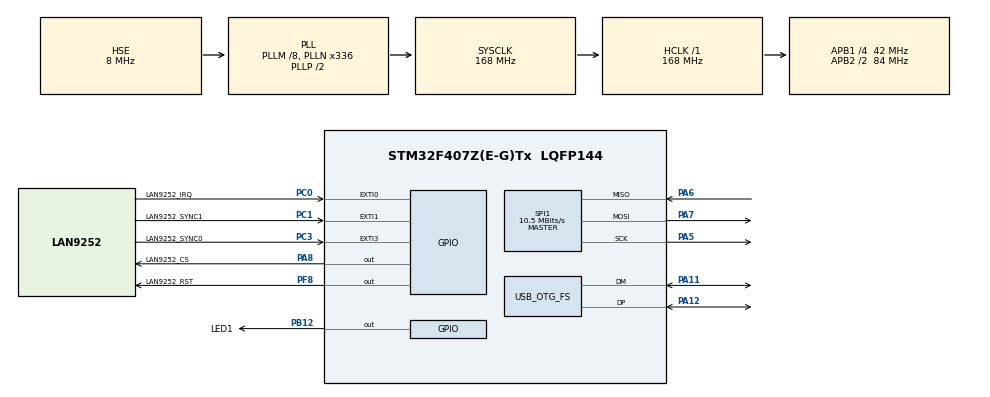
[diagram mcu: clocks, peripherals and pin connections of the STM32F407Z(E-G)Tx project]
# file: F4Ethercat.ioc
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FREERTOS.Tasks01=defaultTask,24,128,StartDefaultTask,Default,NULL,Dynamic,NULL,NULL
Mcu.Family=STM32F4
Mcu.Name=STM32F407Z(E-G)Tx
Mcu.Package=LQFP144
NVIC.EXTI0_IRQn=true\:5\:0\:false\:false\:true\:true\:true\:true\:true
NVIC.EXTI1_IRQn=true\:5\:0\:false\:false\:true\:true\:true\:true\:true
NVIC.EXTI3_IRQn=true\:5\:0\:false\:false\:true\:true\:true\:true\:true
NVIC.OTG_FS_IRQn=true\:5\:0\:false\:false\:true\:true\:false\:true\:true
NVIC.PriorityGroup=NVIC_PRIORITYGROUP_4
PA11.Mode=Device_Only
PA11.Signal=USB_OTG_FS_DM
PA12.Mode=Device_Only
PA12.Signal=USB_OTG_FS_DP
PA13.Mode=Serial_Wire
PA13.Signal=SYS_JTMS-SWDIO
PA14.Mode=Serial_Wire
PA14.Signal=SYS_JTCK-SWCLK
PA5.Mode=Full_Duplex_Master
PA5.Signal=SPI1_SCK
PA6.Mode=Full_Duplex_Master
PA6.Signal=SPI1_MISO
PA7.Mode=Full_Duplex_Master
PA7.Signal=SPI1_MOSI
PA8.GPIO_Label=LAN9252_CS
PA8.GPIO_Speed=GPIO_SPEED_FREQ_VERY_HIGH
PA8.PinState=GPIO_PIN_SET
PA8.Signal=GPIO_Output
PB12.GPIO_Label=LED1
PB12.PinState=GPIO_PIN_SET
PB12.Signal=GPIO_Output
PC0.GPIO_Label=LAN9252_IRQ
PC0.GPIO_ModeDefaultEXTI=GPIO_MODE_IT_FALLING
PC0.GPIO_PuPd=GPIO_PULLUP
PC0.Signal=GPXTI0
PC1.GPIO_Label=LAN9252_SYNC1
PC1.GPIO_ModeDefaultEXTI=GPIO_MODE_IT_FALLING
PC1.GPIO_PuPd=GPIO_PULLUP
PC1.Signal=GPXTI1
PC3.GPIO_Label=LAN9252_SYNC0
PC3.GPIO_ModeDefaultEXTI=GPIO_MODE_IT_FALLING
PC3.GPIO_PuPd=GPIO_PULLUP
PC3.Signal=GPXTI3
PF8.GPIO_Label=LAN9252_RST
PF8.GPIO_ModeDefaultOutputPP=GPIO_MODE_OUTPUT_OD
PF8.PinState=GPIO_PIN_SET
PF8.Signal=GPIO_Output
PH0-OSC_IN.Mode=HSE-External-Oscillator
PH0-OSC_IN.Signal=RCC_OSC_IN
PH1-OSC_OUT.Mode=HSE-External-Oscillator
PH1-OSC_OUT.Signal=RCC_OSC_OUT
ProjectManager.HeapSize=0x400
ProjectManager.StackSize=0x600
ProjectManager.TargetToolchain=CMake
RCC.48MHZClocksFreq_Value=48000000
RCC.AHBFreq_Value=168000000
RCC.APB1CLKDivider=RCC_HCLK_DIV4
RCC.APB1Freq_Value=42000000
RCC.APB1TimFreq_Value=84000000
RCC.APB2CLKDivider=RCC_HCLK_DIV2
RCC.APB2Freq_Value=84000000
RCC.APB2TimFreq_Value=168000000
RCC.CortexFreq_Value=168000000
RCC.HCLKFreq_Value=168000000
RCC.HSE_VALUE=8000000
RCC.HSI_VALUE=16000000
RCC.LSE_VALUE=32768
RCC.PLLM=8
RCC.PLLN=336
RCC.PLLQ=7
RCC.SYSCLKFreq_VALUE=168000000
RCC.SYSCLKSource=RCC_SYSCLKSOURCE_PLLCLK
RCC.VCOOutputFreq_Value=336000000
SPI1.BaudRatePrescaler=SPI_BAUDRATEPRESCALER_8
SPI1.CalculateBaudRate=10.5 MBits/s
SPI1.Direction=SPI_DIRECTION_2LINES
SPI1.Mode=SPI_MODE_MASTER
SPI1.VirtualType=VM_MASTER
USB_DEVICE.CLASS_NAME_FS=CDC
USB_DEVICE.VirtualMode-CDC_FS=Cdc
USB_DEVICE.VirtualModeFS=Cdc_FS
USB_OTG_FS.VirtualMode=Device_Only
VP_FREERTOS_VS_CMSIS_V2.Mode=CMSIS_V2
VP_USB_DEVICE_VS_USB_DEVICE_CDC_FS.Mode=CDC_FS
board=custom

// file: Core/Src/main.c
/* USER CODE BEGIN Header */
/**
  ******************************************************************************
  * @file           : main.c
  * @brief          : Main program body
  ******************************************************************************
  * @attention
  *
  * Copyright (c) 2026 STMicroelectronics.
  * All rights reserved.
  *
  * This software is licensed under terms that can be found in the LICENSE file
  * in the root directory of this software component.
  * If no LICENSE file comes with this software, it is provided AS-IS.
  *
  ******************************************************************************
  */
/* USER CODE END Header */
#include "main.h"
#include "cmsis_os.h"
#include "usb_device.h"

/* USER CODE BEGIN Includes */
#include "ecat_app.h"
/* USER CODE END Includes */

SPI_HandleTypeDef hspi1;

/* Definitions for defaultTask */
osThreadId_t defaultTaskHandle;
const osThreadAttr_t defaultTask_attributes = {
  .name = "defaultTask",
  .stack_size = 128 * 4,
  .priority = (osPriority_t) osPriorityNormal,
};
/* USER CODE BEGIN PV */
osThreadId_t ecatTaskHandle;
const osThreadAttr_t ecatTask_attributes = {
  .name = "ecatTask",
  .stack_size = 1024 * 4,
  .priority = (osPriority_t) osPriorityAboveNormal,
};
/* USER CODE END PV */

void SystemClock_Config(void);
static void MX_GPIO_Init(void);
static void MX_SPI1_Init(void);
void StartDefaultTask(void *argument);

int main(void)
{

  /* MCU Configuration--------------------------------------------------------*/

  /* Reset of all peripherals, Initializes the Flash interface and the Systick. */
  HAL_Init();

  /* Configure the system clock */
  SystemClock_Config();

  /* Initialize all configured peripherals */
  MX_GPIO_Init();
  MX_SPI1_Init();

  /* Init scheduler */
  osKernelInitialize();

  /* Create the thread(s) */
  /* creation of defaultTask */
  defaultTaskHandle = osThreadNew(StartDefaultTask, NULL, &defaultTask_attributes);

  /* USER CODE BEGIN RTOS_THREADS */
  /* add threads, ... */
  ecatTaskHandle = osThreadNew(ecat_app_task, NULL, &ecatTask_attributes);
  /* USER CODE END RTOS_THREADS */

  /* Start scheduler */
  osKernelStart();

  /* We should never get here as control is now taken by the scheduler */

  /* Infinite loop */
  while (1)
  {

  }
}

void SystemClock_Config(void)
{
  RCC_OscInitTypeDef RCC_OscInitStruct = {0};
  RCC_ClkInitTypeDef RCC_ClkInitStruct = {0};

  /** Configure the main internal regulator output voltage
  */
  __HAL_RCC_PWR_CLK_ENABLE();
  __HAL_PWR_VOLTAGESCALING_CONFIG(PWR_REGULATOR_VOLTAGE_SCALE1);

  /** Initializes the RCC Oscillators according to the specified parameters
  * in the RCC_OscInitTypeDef structure.
  */
  RCC_OscInitStruct.OscillatorType = RCC_OSCILLATORTYPE_HSE;
  RCC_OscInitStruct.HSEState = RCC_HSE_ON;
  RCC_OscInitStruct.PLL.PLLState = RCC_PLL_ON;
  RCC_OscInitStruct.PLL.PLLSource = RCC_PLLSOURCE_HSE;
  RCC_OscInitStruct.PLL.PLLM = 8;
  RCC_OscInitStruct.PLL.PLLN = 336;
  RCC_OscInitStruct.PLL.PLLP = RCC_PLLP_DIV2;
  RCC_OscInitStruct.PLL.PLLQ = 7;
  if (HAL_RCC_OscConfig(&RCC_OscInitStruct) != HAL_OK)
  {
    Error_Handler();
  }

  /** Initializes the CPU, AHB and APB buses clocks
  */
  RCC_ClkInitStruct.ClockType = RCC_CLOCKTYPE_HCLK|RCC_CLOCKTYPE_SYSCLK
                              |RCC_CLOCKTYPE_PCLK1|RCC_CLOCKTYPE_PCLK2;
  RCC_ClkInitStruct.SYSCLKSource = RCC_SYSCLKSOURCE_PLLCLK;
  RCC_ClkInitStruct.AHBCLKDivider = RCC_SYSCLK_DIV1;
  RCC_ClkInitStruct.APB1CLKDivider = RCC_HCLK_DIV4;
  RCC_ClkInitStruct.APB2CLKDivider = RCC_HCLK_DIV2;

  if (HAL_RCC_ClockConfig(&RCC_ClkInitStruct, FLASH_LATENCY_5) != HAL_OK)
  {
    Error_Handler();
  }
}

static void MX_SPI1_Init(void)
{

  /* SPI1 parameter configuration*/
  hspi1.Instance = SPI1;
  hspi1.Init.Mode = SPI_MODE_MASTER;
  hspi1.Init.Direction = SPI_DIRECTION_2LINES;
  hspi1.Init.DataSize = SPI_DATASIZE_8BIT;
  hspi1.Init.CLKPolarity = SPI_POLARITY_LOW;
  hspi1.Init.CLKPhase = SPI_PHASE_1EDGE;
  hspi1.Init.NSS = SPI_NSS_SOFT;
  hspi1.Init.BaudRatePrescaler = SPI_BAUDRATEPRESCALER_8;
  hspi1.Init.FirstBit = SPI_FIRSTBIT_MSB;
  hspi1.Init.TIMode = SPI_TIMODE_DISABLE;
  hspi1.Init.CRCCalculation = SPI_CRCCALCULATION_DISABLE;
  hspi1.Init.CRCPolynomial = 10;
  if (HAL_SPI_Init(&hspi1) != HAL_OK)
  {
    Error_Handler();
  }

}

static void MX_GPIO_Init(void)
{
  GPIO_InitTypeDef GPIO_InitStruct = {0};

  /* GPIO Ports Clock Enable */
  __HAL_RCC_GPIOF_CLK_ENABLE();
  __HAL_RCC_GPIOH_CLK_ENABLE();
  __HAL_RCC_GPIOC_CLK_ENABLE();
  __HAL_RCC_GPIOA_CLK_ENABLE();
  __HAL_RCC_GPIOB_CLK_ENABLE();

  /*Configure GPIO pin Output Level */
  HAL_GPIO_WritePin(LAN9252_RST_GPIO_Port, LAN9252_RST_Pin, GPIO_PIN_SET);

  /*Configure GPIO pin Output Level */
  HAL_GPIO_WritePin(LED1_GPIO_Port, LED1_Pin, GPIO_PIN_SET);

  /*Configure GPIO pin Output Level */
  HAL_GPIO_WritePin(LAN9252_CS_GPIO_Port, LAN9252_CS_Pin, GPIO_PIN_SET);

  /*Configure GPIO pin : LAN9252_RST_Pin */
  GPIO_InitStruct.Pin = LAN9252_RST_Pin;
  GPIO_InitStruct.Mode = GPIO_MODE_OUTPUT_OD;
  GPIO_InitStruct.Pull = GPIO_NOPULL;
  GPIO_InitStruct.Speed = GPIO_SPEED_FREQ_LOW;
  HAL_GPIO_Init(LAN9252_RST_GPIO_Port, &GPIO_InitStruct);

  /*Configure GPIO pins : LAN9252_IRQ_Pin LAN9252_SYNC1_Pin LAN9252_SYNC0_Pin */
  GPIO_InitStruct.Pin = LAN9252_IRQ_Pin|LAN9252_SYNC1_Pin|LAN9252_SYNC0_Pin;
  GPIO_InitStruct.Mode = GPIO_MODE_IT_FALLING;
  GPIO_InitStruct.Pull = GPIO_PULLUP;
  HAL_GPIO_Init(GPIOC, &GPIO_InitStruct);

  /*Configure GPIO pin : LED1_Pin */
  GPIO_InitStruct.Pin = LED1_Pin;
  GPIO_InitStruct.Mode = GPIO_MODE_OUTPUT_PP;
  GPIO_InitStruct.Pull = GPIO_NOPULL;
  GPIO_InitStruct.Speed = GPIO_SPEED_FREQ_LOW;
  HAL_GPIO_Init(LED1_GPIO_Port, &GPIO_InitStruct);

  /*Configure GPIO pin : LAN9252_CS_Pin */
  GPIO_InitStruct.Pin = LAN9252_CS_Pin;
  GPIO_InitStruct.Mode = GPIO_MODE_OUTPUT_PP;
  GPIO_InitStruct.Pull = GPIO_NOPULL;
  GPIO_InitStruct.Speed = GPIO_SPEED_FREQ_VERY_HIGH;
  HAL_GPIO_Init(LAN9252_CS_GPIO_Port, &GPIO_InitStruct);

  /* EXTI interrupt init*/
  HAL_NVIC_SetPriority(EXTI0_IRQn, 5, 0);
  HAL_NVIC_EnableIRQ(EXTI0_IRQn);

  HAL_NVIC_SetPriority(EXTI1_IRQn, 5, 0);
  HAL_NVIC_EnableIRQ(EXTI1_IRQn);

  HAL_NVIC_SetPriority(EXTI3_IRQn, 5, 0);
  HAL_NVIC_EnableIRQ(EXTI3_IRQn);

}

void StartDefaultTask(void *argument)
{
  /* init code for USB_DEVICE */
  MX_USB_DEVICE_Init();
  for(;;)
  {
    osDelay(1);
  }
}

void Error_Handler(void)
{
  __disable_irq();
  while (1)
  {
  }
}
